# DA14531 register map
Vendor: Dialog; Series: DA14531; File version: 1.2
CPU: CM0 r1p0, little endian, MPU, FPU, 3 interrupt priority bits
Registers are 16-bit, read-write, reset 0x0 unless marked. A register's access mark holds for its fields unless they carry their own. Offsets are from the block's base; [hi:lo] are bit positions; {n}, {i} and the like mark numbered series; <NAME> marks a mode.

## CRG_TIM — CRG_TIM registers
Base 0x50004200
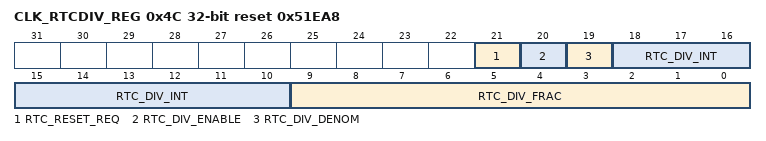
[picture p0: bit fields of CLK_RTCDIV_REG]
0x4C CLK_RTCDIV_REG 32-bit reset 0x51EA8 — Divisor for RTC 100Hz clock
  [21] RTC_RESET_REQ — Reset request for the RTC module
  [20] RTC_DIV_ENABLE — Enable for the 100 Hz generation for the RTC block
  [19] RTC_DIV_DENOM — Selects the denominator for the fractional division: 0b0: 1000 0b1: 1024
  [18:10] RTC_DIV_INT — Integer divisor part for RTC 100Hz generation
  [9:0] RTC_DIV_FRAC — Fractional divisor part for RTC 100Hz generation. if RTC_DIV_DENOM=1, <RTC_DIV_FRAC> out of 1024 cycles will divide by <RTC_DIV_INT+1>, the rest is <RTC_DIV_INT> If RTC_DIV_DENOM=0, <RTC_DIV_FRAC> out of 1000 cycles will divide by <RTC_DIV_INT+1>, the rest is <RTC_DIV_INT>

## KBRD — KBRD registers
Base 0x50001400
0x00 GPIO_IRQ0_IN_SEL_REG — GPIO interrupt selection for GPIO_IRQ0
  [3:0] KBRD_IRQ0_SEL — input selection that can generate a GPIO interrupt 1: P0[0] is selected 2: P0[1] is selected 3: P0[2] is selected 4: P0[3] is selected 5: P0[4] is selected 6: P0[5] is selected 7: P0[6] is selected 8: P0[7] is selected 9: P0[8] is selected 10: P0[9] is selected 11: P0[10] is selected 12: P0[11] is selected all others: no input selected
{0x0+2i} GPIO_IRQ{i}_IN_SEL_REG (i=1..4) — GPIO interrupt selection for GPIO_IRQ{i}
  [3:0] KBRD_IRQ{i}_SEL — see KBRD_IRQ0_SEL
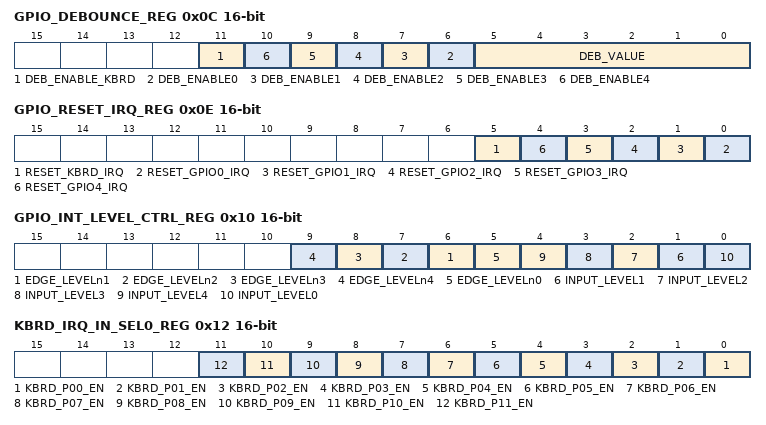
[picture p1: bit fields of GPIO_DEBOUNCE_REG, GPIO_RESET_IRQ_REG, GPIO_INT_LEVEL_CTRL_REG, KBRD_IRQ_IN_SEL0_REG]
0x0C GPIO_DEBOUNCE_REG — debounce counter value for GPIO inputs
  [11] DEB_ENABLE_KBRD — enables the debounce counter for the KBRD interface
  [n+6] DEB_ENABLE{n} (n=0..4) — enables the debounce counter for GPIO IRQ{n}
  [5:0] DEB_VALUE — Keyboard debounce time if enabled. Generate KEYB_INT after specified time. Debounce time: N*1 ms. N =0..63
0x0E GPIO_RESET_IRQ_REG — GPIO interrupt reset register
  [5] RESET_KBRD_IRQ wo — writing a 1 to this bit will reset the KBRD IRQ. Reading returns 0.
  [n] RESET_GPIO{n}_IRQ wo (n=0..4) — writing a 1 to this bit will reset the GPIO{n} IRQ. Reading returns 0.
0x10 GPIO_INT_LEVEL_CTRL_REG — high or low level select for GPIO interrupts
  [n+5] EDGE_LEVELn{n} (n=1..4) — see EDGE_LEVELn0, but for GPIO IRQ{n}
  [5] EDGE_LEVELn0 — 0: do not wait for key release after interrupt was reset for GPIO IRQ0, so a new interrupt can be initiated immediately 1: wait for key release after interrupt was reset for IRQ0
  [n] INPUT_LEVEL{n} (n=1..4) — see INPUT_LEVEL0, but for GPIO IRQ{n}
  [0] INPUT_LEVEL0 — 0 = selected input will generate GPIO IRQ0 if that input is high. 1 = selected input will generate GPIO IRQ0 if that input is low.
0x12 KBRD_IRQ_IN_SEL0_REG — GPIO interrupt selection for KBRD_IRQ for P0
  [n] KBRD_P{n:02}_EN (n=0..11) — enable P0[{n}] for the keyboard interrupt
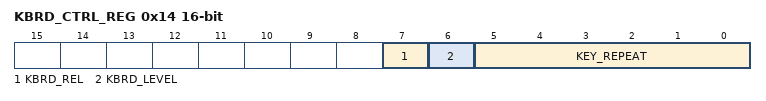
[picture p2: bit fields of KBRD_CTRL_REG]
0x14 KBRD_CTRL_REG — GPIO Kbrd control register
  [7] KBRD_REL — 0 = No interrupt on key release 1 = Interrupt also on key release (also debouncing if enabled)
  [6] KBRD_LEVEL — 0 = enabled input will generate KBRD IRQ if that input is high. 1 = enabled input will generate KBRD IRQ if that input is low.
  [5:0] KEY_REPEAT — While key is pressed, automatically generate repeating KEYB_INT after specified time unequal to 0. Repeat time: N*1 ms. N =1..63, N=0 disables the timer.

## MBIST_SRAM12 — MBIST_SRAM12 registers
Base 0x50003700
0x00 MBIST_SRAM12_ADDR_REG
  [0] MBIST_ADDR ro — Returns the current address register in case of a mismatch.
0x02 MBIST_SRAM12_STATE_REG
  [0] MBIST_STATE ro — Returns the current state in case of a mismatch.
0x04 MBIST_SRAM12_RD_MSB_REG
  [0] MBIST_MSB_DATA ro — Returns the actual MSB read data in case of a mismatch.
0x06 MBIST_SRAM12_RD_LSB_REG
  [0] MBIST_LSB_DATA ro — Returns the actual LSB read data in case of a mismatch.

## MBIST_SRAM3 — MBIST_SRAM3 registers
Base 0x50003800
Registers as MBIST_SRAM12 (with MBIST_SRAM12 read as MBIST_SRAM3).
